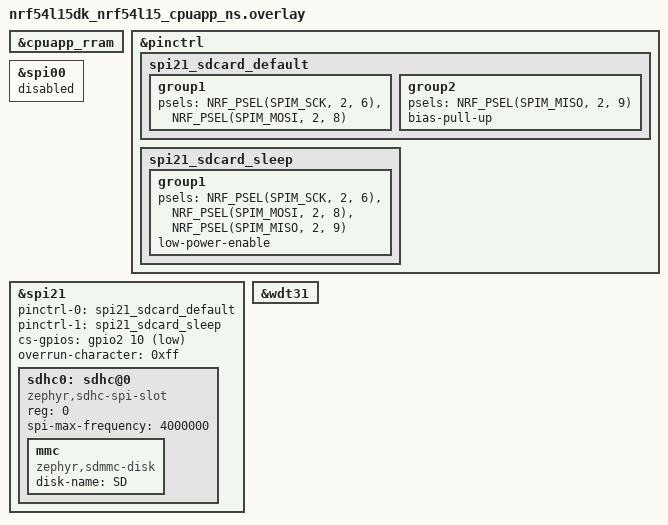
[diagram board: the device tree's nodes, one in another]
// Copyright (C) 2025 milrt <milrt@proton.me>
// SPDX-License-Identifier: GPL-3.0-or-later

&cpuapp_rram {
    /delete-node/ partitions;
};

#include "sigu_partitions.dtsi"

&pinctrl {
    spi21_sdcard_default: spi21_sdcard_default {
        group1 {
            psels = <NRF_PSEL(SPIM_SCK, 2, 6)>, <NRF_PSEL(SPIM_MOSI, 2, 8)>;
        };

        group2 {
            psels = <NRF_PSEL(SPIM_MISO, 2, 9)>;
            bias-pull-up;
        };
    };

    spi21_sdcard_sleep: spi21_sdcard_sleep {
        group1 {
            psels = <NRF_PSEL(SPIM_SCK, 2, 6)>, <NRF_PSEL(SPIM_MOSI, 2, 8)>,
                    <NRF_PSEL(SPIM_MISO, 2, 9)>;
            low-power-enable;
        };
    };
};

&spi00 {
    status = "disabled";
    /delete-node/ mx25r6435f@0;
};

&spi21 {
    status = "okay";
    pinctrl-0 = <&spi21_sdcard_default>;
    pinctrl-1 = <&spi21_sdcard_sleep>;
    pinctrl-names = "default", "sleep";
    cs-gpios = <&gpio2 10 GPIO_ACTIVE_LOW>;
    overrun-character = <0xff>;

    sdhc0: sdhc@0 {
        compatible = "zephyr,sdhc-spi-slot";
        reg = <0>;
        status = "okay";
        spi-max-frequency = <4000000>;

        mmc {
            compatible = "zephyr,sdmmc-disk";
            disk-name = "SD";
            status = "okay";
        };
    };
};

// NS watchdog (watchdog0). WDT30 is secure in hardware.
&wdt31 {
    status = "okay";
};
